# STM32MP153 register map
File version: 1.3
CPU: CM4 r0p1, little endian, no MPU, FPU, 4 interrupt priority bits
Registers are 32-bit, read-write, reset 0x0 unless marked. A register's access mark holds for its fields unless they carry their own. Offsets are from the block's base; [hi:lo] are bit positions; {n}, {i} and the like mark numbered series.

## FDCAN1
Base 0x4400E000
Same registers: FDCAN2 0x4400F000
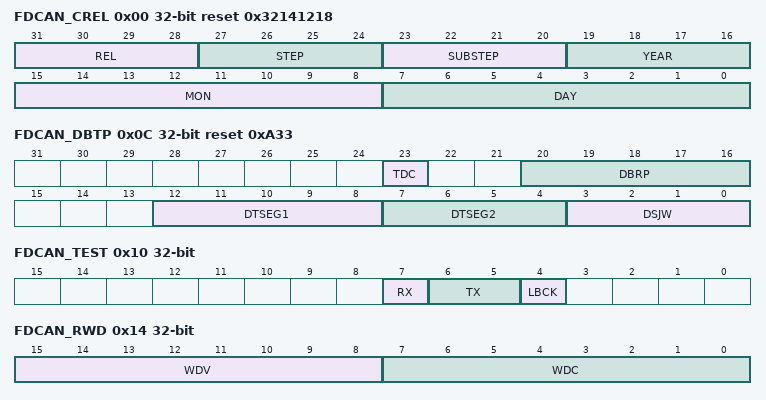
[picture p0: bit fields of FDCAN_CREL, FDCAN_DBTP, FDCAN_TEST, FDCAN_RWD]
0x00 FDCAN_CREL ro reset 0x32141218 — FDCAN core release register
  [31:28] REL, [27:24] STEP, [23:20] SUBSTEP, [19:16] YEAR, [15:8] MON, [7:0] DAY
0x04 FDCAN_ENDN ro reset 0x87654321 — FDCAN Endian register
  [31:0] ETV
0x0C FDCAN_DBTP reset 0xA33 — This register is dedicated to data bit timing phase and only writable if bits FDCAN_CCCR.CCE and FDCAN_CCCR.INIT are set. The CAN time quantum may be programmed in the range from 1 to 32 FDCAN clock periods. tq = (DBRP + 1) FDCAN clock periods. DTSEG1 is the sum of Prop_Seg and Phase_Seg1. DTSEG2 is Phase_Seg2. Therefore the length of the bit time is (DTSEG1 + DTSEG2 + 3) tq for programmed values, or (Sync_Seg+Prop_Seg+Phase_Seg1+Phase_Seg2) tq for functional values. The information processing time (IPT) is zero, meaning the data for the next bit is available at the first clock edge after the sample point.
  [23] TDC, [20:16] DBRP, [12:8] DTSEG1, [7:4] DTSEG2, [3:0] DSJW
0x10 FDCAN_TEST access per field — Write access to this register has to be enabled by setting bit FDCAN_CCCR.TEST to 1. All register functions are set to their reset values when bit FDCAN_CCCR.TEST is reset. Loop back mode and software control of Tx pin FDCANx_TX are hardware test modes. Programming TX differently from 00 may disturb the message transfer on the CAN bus.
  [7] RX ro, [6:5] TX rw, [4] LBCK rw
0x14 FDCAN_RWD access per field — The RAM watchdog monitors the READY output of the message RAM. A message RAM access starts the message RAM watchdog counter with the value configured by the FDCAN_RWD.WDC bits. The counter is reloaded with FDCAN_RWD.WDC bits when the message RAM signals successful completion by activating its READY output. In case there is no response from the message RAM until the counter has counted down to 0, the counter stops and interrupt flag FDCAN_IR.WDI bit is set. The RAM watchdog counter is clocked by the fdcan_pclk clock.
  [15:8] WDV ro, [7:0] WDC rw
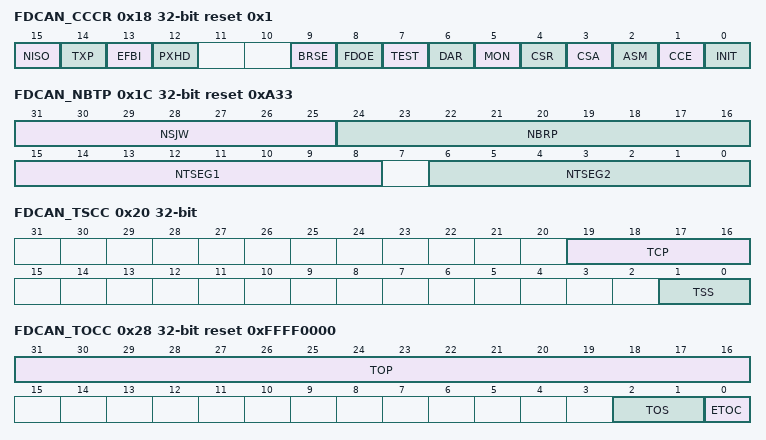
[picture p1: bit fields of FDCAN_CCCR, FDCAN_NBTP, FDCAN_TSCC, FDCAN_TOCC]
0x18 FDCAN_CCCR access per field reset 0x1 — For details about setting and resetting of single bits see Software initialization.
  [15] NISO rw, [14] TXP rw, [13] EFBI rw, [12] PXHD rw, [9] BRSE rw, [8] FDOE rw, [7] TEST rw, [6] DAR rw, [5] MON rw, [4] CSR rw, [3] CSA ro, [2] ASM rw, [1] CCE rw, [0] INIT rw
0x1C FDCAN_NBTP reset 0xA33 — This register is dedicated to the nominal bit timing used during the arbitration phase.
  [31:25] NSJW, [24:16] NBRP, [15:8] NTSEG1, [6:0] NTSEG2
0x20 FDCAN_TSCC — FDCAN timestamp counter configuration register
  [19:16] TCP, [1:0] TSS
0x24 FDCAN_TSCV — FDCAN timestamp counter value register
  [15:0] TSC
0x28 FDCAN_TOCC reset 0xFFFF0000 — FDCAN timeout counter configuration register
  [31:16] TOP, [2:1] TOS, [0] ETOC
0x2C FDCAN_TOCV reset 0xFFFF — FDCAN timeout counter value register
  [15:0] TOC
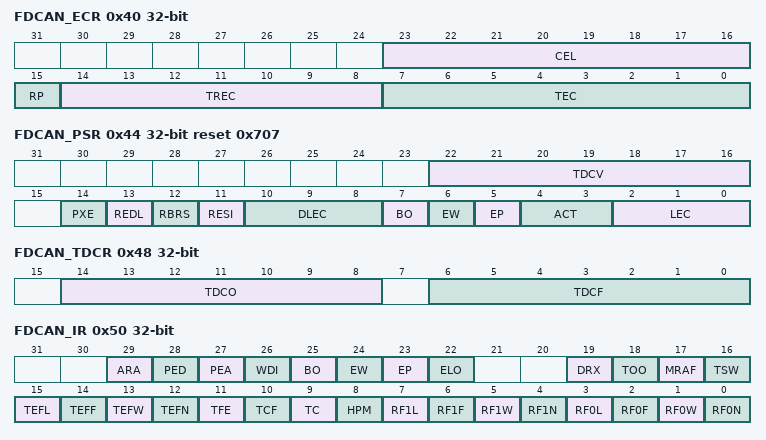
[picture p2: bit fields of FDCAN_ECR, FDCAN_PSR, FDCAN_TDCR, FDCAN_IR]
0x40 FDCAN_ECR access per field — FDCAN error counter register
  [23:16] CEL rw, [15] RP ro, [14:8] TREC ro, [7:0] TEC ro
0x44 FDCAN_PSR access per field reset 0x707 — FDCAN protocol status register
  [22:16] TDCV ro, [14] PXE rw, [13] REDL rw, [12] RBRS rw, [11] RESI rw, [10:8] DLEC ro, [7] BO ro, [6] EW ro, [5] EP ro, [4:3] ACT ro, [2:0] LEC ro
0x48 FDCAN_TDCR — FDCAN transmitter delay compensation register
  [14:8] TDCO, [6:0] TDCF
0x50 FDCAN_IR — The flags are set when one of the listed conditions is detected (edge-sensitive). The flags remain set until the Host clears them. A flag is cleared by writing a 1 to the corresponding bit position. Writing a 0 has no effect. A hard reset will clear the register. The configuration of IE controls whether an interrupt is generated. The configuration of ILS controls on which interrupt line an interrupt is signaled.
  [29] ARA, [28] PED, [27] PEA, [26] WDI, [25] BO, [24] EW, [23] EP, [22] ELO, [19] DRX, [18] TOO, [17] MRAF, [16] TSW, [15] TEFL, [14] TEFF, [13] TEFW, [12] TEFN, [11] TFE, [10] TCF, [9] TC, [8] HPM, [7] RF1L, [6] RF1F, [5] RF1W, [4] RF1N, [3] RF0L, [2] RF0F, [1] RF0W, [0] RF0N
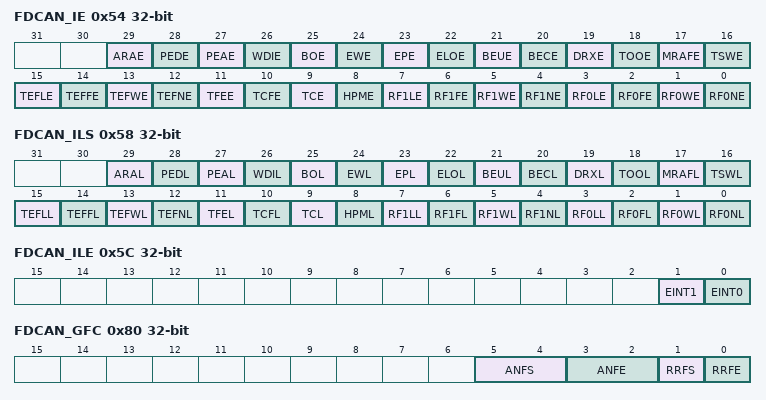
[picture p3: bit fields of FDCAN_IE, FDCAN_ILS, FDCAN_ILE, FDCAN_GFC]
0x54 FDCAN_IE — The settings in the interrupt enable register determine which status changes in the interrupt register will be signaled on an interrupt line.
  [29] ARAE, [28] PEDE, [27] PEAE, [26] WDIE, [25] BOE, [24] EWE, [23] EPE, [22] ELOE, [21] BEUE, [20] BECE, [19] DRXE, [18] TOOE, [17] MRAFE, [16] TSWE, [15] TEFLE, [14] TEFFE, [13] TEFWE, [12] TEFNE, [11] TFEE, [10] TCFE, [9] TCE, [8] HPME, [7] RF1LE, [6] RF1FE, [5] RF1WE, [4] RF1NE, [3] RF0LE, [2] RF0FE, [1] RF0WE, [0] RF0NE
0x58 FDCAN_ILS — This register assigns an interrupt generated by a specific interrupt flag from the interrupt register to one of the two module interrupt lines. For interrupt generation the respective interrupt line has to be enabled via FDCAN_ILE.EINT0 and FDCAN_ILE.EINT1.
  [29] ARAL, [28] PEDL, [27] PEAL, [26] WDIL, [25] BOL, [24] EWL, [23] EPL, [22] ELOL, [21] BEUL, [20] BECL, [19] DRXL, [18] TOOL, [17] MRAFL, [16] TSWL, [15] TEFLL, [14] TEFFL, [13] TEFWL, [12] TEFNL, [11] TFEL, [10] TCFL, [9] TCL, [8] HPML, [7] RF1LL, [6] RF1FL, [5] RF1WL, [4] RF1NL, [3] RF0LL, [2] RF0FL, [1] RF0WL, [0] RF0NL
0x5C FDCAN_ILE — Each of the two interrupt lines to the CPU can be enabled/disabled separately by programming bits EINT0 and EINT1.
  [1] EINT1, [0] EINT0
0x80 FDCAN_GFC — Global settings for message ID filtering. The global filter configuration register controls the filter path for standard and extended messages as described in Figure708: Standard message ID filter path and Figure709: Extended message ID filter path.
  [5:4] ANFS, [3:2] ANFE, [1] RRFS, [0] RRFE
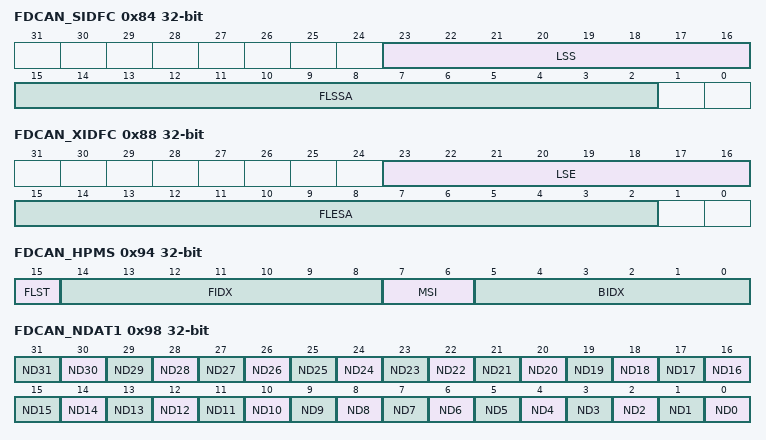
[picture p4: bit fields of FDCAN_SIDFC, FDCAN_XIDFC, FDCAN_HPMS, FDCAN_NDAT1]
0x84 FDCAN_SIDFC — Settings for 11-bit standard message ID filtering.The standard ID filter configuration register controls the filter path for standard messages as described in Figure708.
  [23:16] LSS, [15:2] FLSSA
0x88 FDCAN_XIDFC — Settings for 29-bit extended message ID filtering. The FDCAN extended ID filter configuration register controls the filter path for standard messages as described in Figure709: Extended message ID filter path.
  [23:16] LSE, [15:2] FLESA
0x90 FDCAN_XIDAM reset 0x1FFFFFFF — FDCAN extended ID and mask register
  [28:0] EIDM
0x94 FDCAN_HPMS ro — This register is updated every time a message ID filter element configured to generate a priority event match. This can be used to monitor the status of incoming high priority messages and to enable fast access to these messages.
  [15] FLST, [14:8] FIDX, [7:6] MSI, [5:0] BIDX
0x98 FDCAN_NDAT1 — FDCAN new data 1 register
  [n] ND{n} (n=0..31)
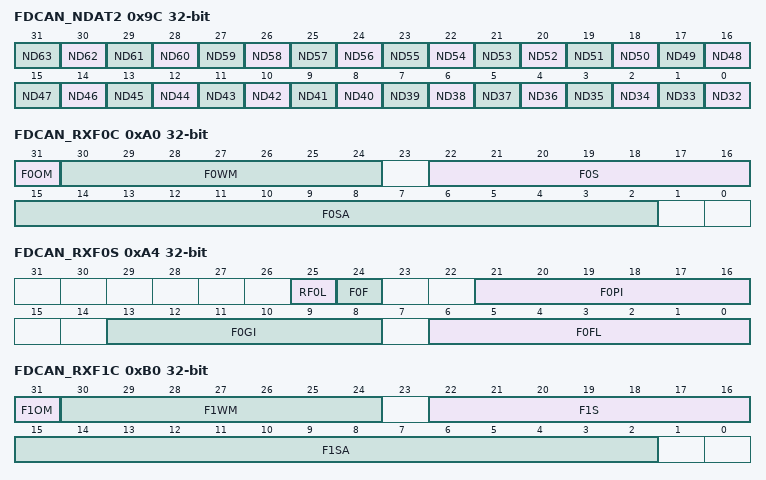
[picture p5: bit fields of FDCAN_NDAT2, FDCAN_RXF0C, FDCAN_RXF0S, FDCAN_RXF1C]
0x9C FDCAN_NDAT2 — FDCAN new data 2 register
  [n-32] ND{n} (n=32..63)
0xA0 FDCAN_RXF0C — FDCAN Rx FIFO 0 configuration register
  [31] F0OM, [30:24] F0WM, [22:16] F0S, [15:2] F0SA
0xA4 FDCAN_RXF0S — FDCAN Rx FIFO 0 status register
  [25] RF0L, [24] F0F, [21:16] F0PI, [13:8] F0GI, [6:0] F0FL
0xA8 FDCAN_RXF0A — FDCAN Rx FIFO 0 acknowledge register
  [5:0] F0AI
0xAC FDCAN_RXBC — FDCAN Rx buffer configuration register
  [15:2] RBSA
0xB0 FDCAN_RXF1C — FDCAN Rx FIFO 1 configuration register
  [31] F1OM, [30:24] F1WM, [22:16] F1S, [15:2] F1SA
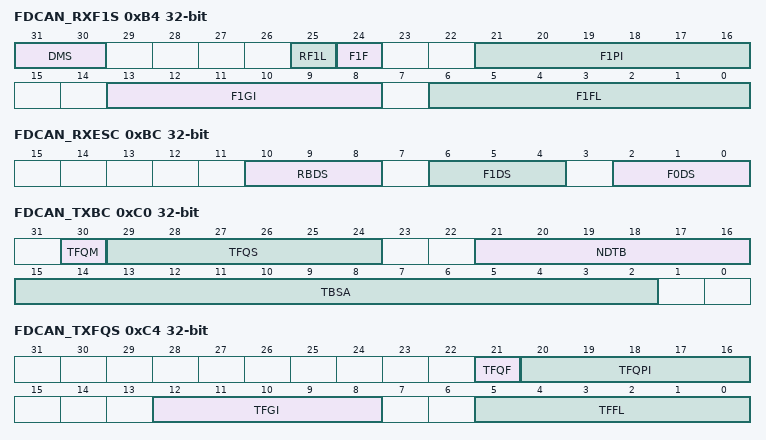
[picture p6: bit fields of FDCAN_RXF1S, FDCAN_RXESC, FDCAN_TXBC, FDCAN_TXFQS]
0xB4 FDCAN_RXF1S ro — FDCAN Rx FIFO 1 status register
  [31:30] DMS, [25] RF1L, [24] F1F, [21:16] F1PI, [13:8] F1GI, [6:0] F1FL
0xB8 FDCAN_RXF1A — FDCAN Rx FIFO 1 acknowledge register
  [5:0] F1AI
0xBC FDCAN_RXESC ro — Configures the number of data bytes belonging to an Rx buffer / Rx FIFO element. Data field sizes higher than 8 bytes are intended for CAN FD operation only.
  [10:8] RBDS, [6:4] F1DS, [2:0] F0DS
0xC0 FDCAN_TXBC — FDCAN Tx buffer configuration register
  [30] TFQM, [29:24] TFQS, [21:16] NDTB, [15:2] TBSA
0xC4 FDCAN_TXFQS ro — The Tx FIFO/queue status is related to the pending Tx requests listed in register FDCAN_TXBRP. Therefore the effect of add/cancellation requests may be delayed due to a running Tx scan (FDCAN_TXBRP not yet updated).
  [21] TFQF, [20:16] TFQPI, [12:8] TFGI, [5:0] TFFL
0xC8 FDCAN_TXESC ro — Configures the number of data bytes belonging to a Tx buffer element. Data field sizes >8 bytes are intended for CAN FD operation only.
  [2:0] TBDS
0xD0 FDCAN_TXBAR — FDCAN Tx buffer add request register
  [31:0] AR
0xD4 FDCAN_TXBCR — FDCAN Tx buffer cancellation request register
  [31:0] CR
0xD8 FDCAN_TXBTO ro — FDCAN Tx buffer transmission occurred register
  [31:0] TO
0xDC FDCAN_TXBCF ro — FDCAN Tx buffer cancellation finished register
  [31:0] CF
0xE0 FDCAN_TXBTIE — FDCAN Tx buffer transmission interrupt enable register
  [31:0] TIE
0xE4 FDCAN_TXBCIE — FDCAN Tx buffer cancellation finished interrupt enable register
  [31:0] CFIE
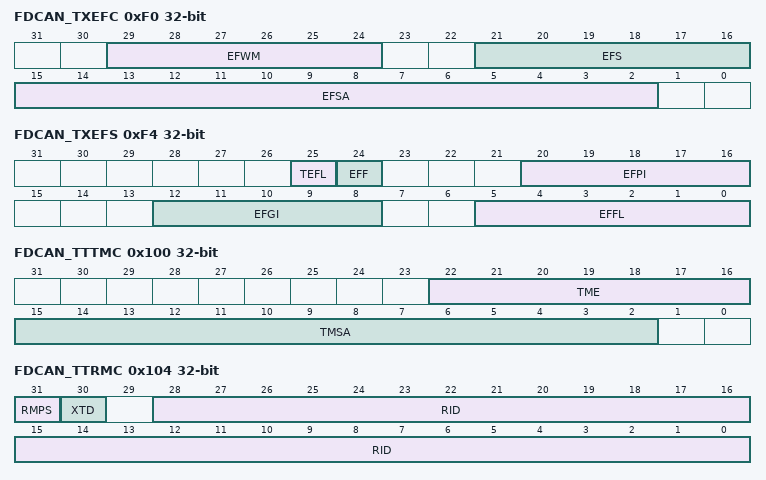
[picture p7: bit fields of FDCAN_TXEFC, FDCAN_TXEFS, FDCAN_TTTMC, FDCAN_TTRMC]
0xF0 FDCAN_TXEFC — FDCAN Tx event FIFO configuration register
  [29:24] EFWM, [21:16] EFS, [15:2] EFSA
0xF4 FDCAN_TXEFS ro — FDCAN Tx event FIFO status register
  [25] TEFL, [24] EFF, [20:16] EFPI, [12:8] EFGI, [5:0] EFFL
0xF8 FDCAN_TXEFA — FDCAN Tx event FIFO acknowledge register
  [4:0] EFAI
0x100 FDCAN_TTTMC — FDCAN TT trigger memory configuration register
  [22:16] TME, [15:2] TMSA
0x104 FDCAN_TTRMC — FDCAN TT reference message configuration register
  [31] RMPS, [30] XTD, [28:0] RID
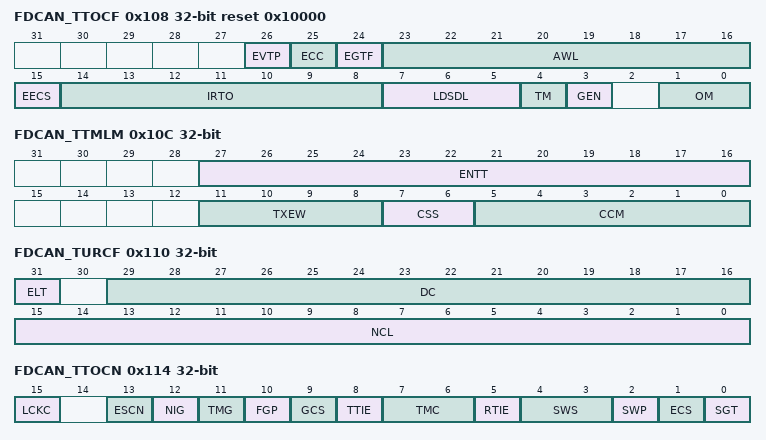
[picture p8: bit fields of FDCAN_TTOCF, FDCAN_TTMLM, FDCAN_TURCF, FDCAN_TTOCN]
0x108 FDCAN_TTOCF reset 0x10000 — FDCAN TT operation configuration register
  [26] EVTP, [25] ECC, [24] EGTF, [23:16] AWL, [15] EECS, [14:8] IRTO, [7:5] LDSDL, [4] TM, [3] GEN, [1:0] OM
0x10C FDCAN_TTMLM — FDCAN TT matrix limits register
  [27:16] ENTT, [11:8] TXEW, [7:6] CSS, [5:0] CCM
0x110 FDCAN_TURCF — The length of the NTU is given by: NTU = CAN clock period x NC/DC. NC is an 18-bit value. Its high part, NCH[17:16] is hard wired to 0b01. Therefore the range of NC extends from 0x10000 to 0x1FFFF. The value configured by NCL is the initial value for FDCAN_TURNA.NAV[15:0]. DC is set to 0x1000 by hardware reset and it may not be written to 0x0000. Level 1: NC 4 * DC and NTU = CAN bit time Levels 0 and 2: NC 8 * DC The actual value of FDCAN_TUR may be changed by the clock drift compensation function of TTCAN level 0 and level 2 in order to adjust the node local view of the NTU to the time master view of the NTU. DC will not be changed by the automatic drift compensation, FDCAN_TURNA.NAV may be adjusted around NC in the range of the synchronization deviation limit given by FDCAN_TTOCF.LDSDL. NC and DC should be programmed to the largest suitable values in achieve the best computational accuracy for the drift compensation process.
  [31] ELT, [29:16] DC, [15:0] NCL
0x114 FDCAN_TTOCN access per field — FDCAN TT operation control register
  [15] LCKC ro, [13] ESCN rw, [12] NIG rw, [11] TMG rw, [10] FGP rw, [9] GCS rw, [8] TTIE rw, [7:6] TMC rw, [5] RTIE rw, [4:3] SWS rw, [2] SWP rw, [1] ECS rw, [0] SGT rw
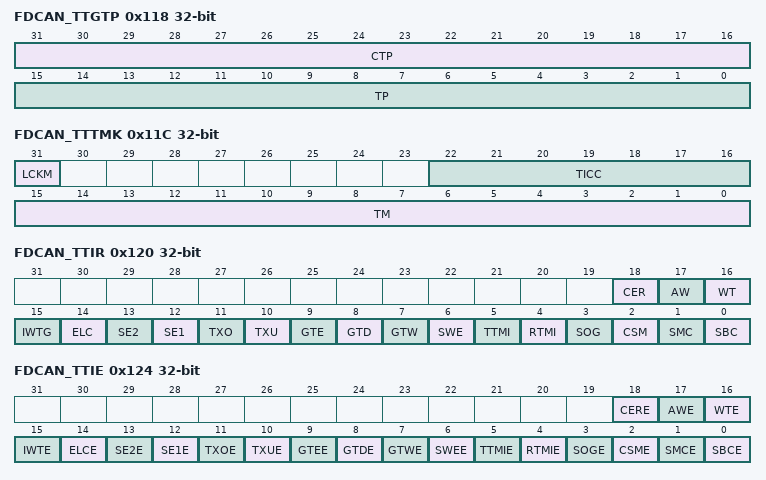
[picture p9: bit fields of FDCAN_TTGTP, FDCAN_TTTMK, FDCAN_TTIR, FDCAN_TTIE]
0x118 FDCAN_TTGTP — If TTOST.WGDT is set, the next reference message will be transmitted with the Master_Ref_Mark modified by the preset value and with Disc_Bit = 1, presetting the global time in all nodes simultaneously. TP is reset to 0x0000 each time a reference message with Disc_Bit = 1 becomes valid or if the node is not the current time master. TP is locked while FDCAN_TTOST.WGTD = 1 after setting FDCAN_TTOCN.SGT until the reference message with Disc_Bit = 1 becomes valid or until the node is no longer the current time master.
  [31:16] CTP, [15:0] TP
0x11C FDCAN_TTTMK access per field — A time mark interrupt (FDCAN_TTIR.TMI = 1) is generated when the time base indicated by FDCAN_TTOCN.TMC (cycle time, local time, or global time) has the same value as TM.
  [31] LCKM ro, [22:16] TICC rw, [15:0] TM rw
0x120 FDCAN_TTIR — The flags are set when one of the listed conditions is detected (edge-sensitive). The flags remain set until the Host clears them. A flag is cleared by writing a 1 to the corresponding bit position. Writing a 0 has no effect. A hard reset will clear the register.
  [18] CER, [17] AW, [16] WT, [15] IWTG, [14] ELC, [13] SE2, [12] SE1, [11] TXO, [10] TXU, [9] GTE, [8] GTD, [7] GTW, [6] SWE, [5] TTMI, [4] RTMI, [3] SOG, [2] CSM, [1] SMC, [0] SBC
0x124 FDCAN_TTIE — The settings in the TT interrupt enable register determine which status changes in the TT interrupt register will result in an interrupt.
  [18] CERE, [17] AWE, [16] WTE, [15] IWTE, [14] ELCE, [13] SE2E, [12] SE1E, [11] TXOE, [10] TXUE, [9] GTEE, [8] GTDE, [7] GTWE, [6] SWEE, [5] TTMIE, [4] RTMIE, [3] SOGE, [2] CSME, [1] SMCE, [0] SBCE
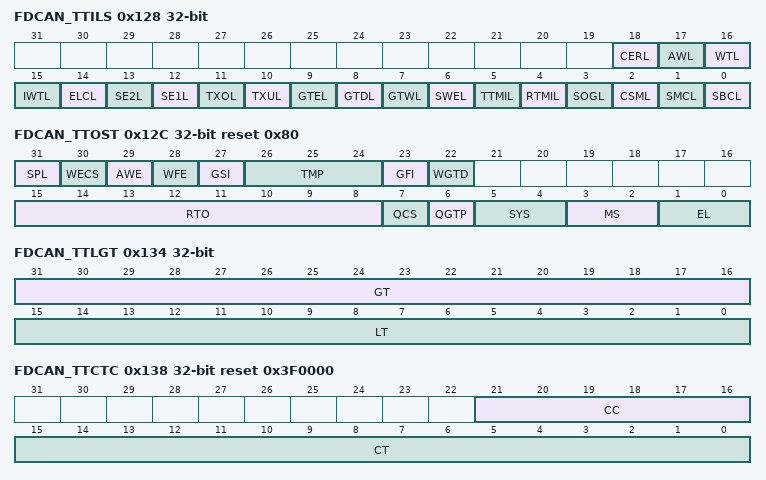
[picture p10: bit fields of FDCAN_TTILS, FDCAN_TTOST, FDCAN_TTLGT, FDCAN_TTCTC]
0x128 FDCAN_TTILS — The TT interrupt Line select register assigns an interrupt generated by a specific interrupt flag from the TT interrupt register to one of the two module interrupt lines. For interrupt generation the respective interrupt line has to be enabled via FDCAN_ILE.EINT0 and FDCAN_ILE.EINT1.
  [18] CERL, [17] AWL, [16] WTL, [15] IWTL, [14] ELCL, [13] SE2L, [12] SE1L, [11] TXOL, [10] TXUL, [9] GTEL, [8] GTDL, [7] GTWL, [6] SWEL, [5] TTMIL, [4] RTMIL, [3] SOGL, [2] CSML, [1] SMCL, [0] SBCL
0x12C FDCAN_TTOST ro reset 0x80 — FDCAN TT operation status register
  [31] SPL, [30] WECS, [29] AWE, [28] WFE, [27] GSI, [26:24] TMP, [23] GFI, [22] WGTD, [15:8] RTO, [7] QCS, [6] QGTP, [5:4] SYS, [3:2] MS, [1:0] EL
0x130 FDCAN_TURNA ro — There is no drift compensation in TTCAN level 1.
  [17:0] NAV
0x134 FDCAN_TTLGT ro — FDCAN TT local and global time register
  [31:16] GT, [15:0] LT
0x138 FDCAN_TTCTC ro reset 0x3F0000 — FDCAN TT cycle time and count register
  [21:16] CC, [15:0] CT
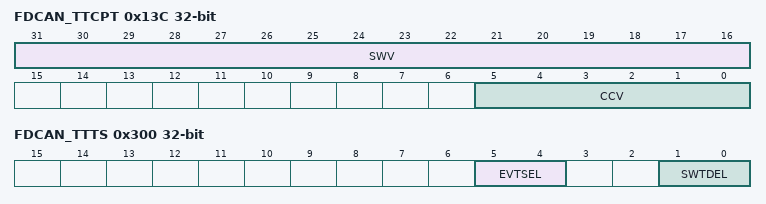
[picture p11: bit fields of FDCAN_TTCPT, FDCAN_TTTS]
0x13C FDCAN_TTCPT ro — FDCAN TT capture time register
  [31:16] SWV, [5:0] CCV
0x140 FDCAN_TTCSM ro — FDCAN TT cycle sync mark register
  [15:0] CSM
0x300 FDCAN_TTTS — The settings in the FDCAN_TTTS register select the input to be used as event trigger and stop watch trigger.
  [5:4] EVTSEL, [1:0] SWTDEL
